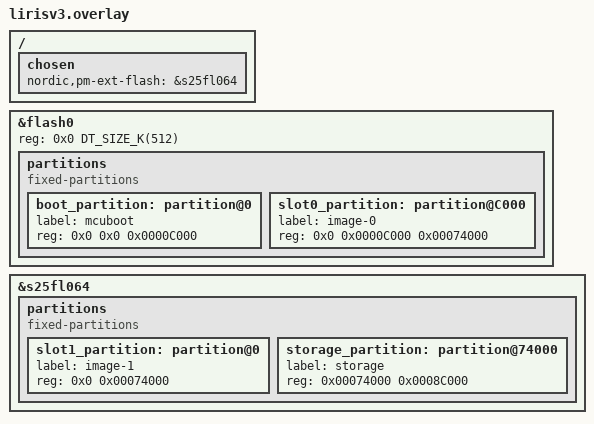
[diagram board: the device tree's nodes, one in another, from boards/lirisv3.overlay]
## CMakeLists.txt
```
#-------------------------------------------------------------------------------
# Zephyr Example Application
#
# Copyright (c) 2021 Nordic Semiconductor ASA
# SPDX-License-Identifier: Apache-2.0

cmake_minimum_required(VERSION 3.13.1)
find_package(Zephyr REQUIRED HINTS $ENV{ZEPHYR_BASE})

project(app LANGUAGES CXX C)

# Add C++ compiler flags
target_compile_options(app PRIVATE
  $<$<COMPILE_LANGUAGE:CXX>:-fno-threadsafe-statics>
)

target_sources(app PRIVATE src/main.cpp)
target_sources_ifdef(CONFIG_MCUMGR_TRANSPORT_BT app PRIVATE src/bluetooth.cpp)
```

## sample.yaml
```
# This file is provided so that the application can be compiled using Twister,
# the Zephyr testing tool. In this file, multiple combinations can be specified,
# so that you can easily test all of them locally or in CI.
sample:
  description: Example application
  name: example-application 
common:
  build_only: true
  integration_platforms:
    - lirisv4
tests:
  app.default: {}
  app.debug:
    extra_overlay_confs:
      - debug.conf
```

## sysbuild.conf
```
# Enable MCUboot bootloader support
SB_CONFIG_BOOTLOADER_MCUBOOT=y
```

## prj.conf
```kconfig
# Bootloader
CONFIG_BOOTLOADER_MCUBOOT=y

# C++ Support
CONFIG_CPP=y
CONFIG_STD_CPP11=y
# Disable everything that causes TLS / heavy runtime
CONFIG_CPP_EXCEPTIONS=n
CONFIG_CPP_RTTI=n
CONFIG_NEWLIB_LIBC=n
CONFIG_MINIMAL_LIBC=y

# Avoid TLS entirely
CONFIG_THREAD_LOCAL_STORAGE=n

# No heap / malloc
CONFIG_HEAP_MEM_POOL_SIZE=0

# MCUmgr and dependencies
CONFIG_NET_BUF=y
CONFIG_ZCBOR=y
CONFIG_CRC=y
CONFIG_MCUMGR=y
CONFIG_STREAM_FLASH=y
CONFIG_FLASH_MAP=y
CONFIG_IMG_MANAGER=y
CONFIG_MCUMGR_GRP_IMG=y
CONFIG_MCUMGR_GRP_OS=y
CONFIG_MCUMGR_GRP_OS_MCUMGR_PARAMS=y
CONFIG_MCUMGR_GRP_ZBASIC=y

# Bluetooth
CONFIG_BT=y
CONFIG_BT_PERIPHERAL=y
CONFIG_BT_L2CAP_TX_MTU=498
CONFIG_BT_BUF_EVT_RX_COUNT=4
CONFIG_BT_BUF_EVT_RX_SIZE=68
CONFIG_BT_BUF_ACL_TX_COUNT=3
CONFIG_BT_BUF_ACL_RX_SIZE=502
CONFIG_BT_BUF_ACL_TX_SIZE=502
CONFIG_BT_BUF_CMD_TX_COUNT=2
CONFIG_BT_CTLR_DATA_LENGTH_MAX=251

# MCUmgr Bluetooth transport
CONFIG_MCUMGR_TRANSPORT_BT=y
CONFIG_MCUMGR_TRANSPORT_BT_CONN_PARAM_CONTROL=y
CONFIG_MCUMGR_TRANSPORT_BT_REASSEMBLY=y
CONFIG_MCUMGR_TRANSPORT_NETBUF_SIZE=1024
CONFIG_MCUMGR_TRANSPORT_WORKQUEUE_STACK_SIZE=2048

# Flash and SPI
CONFIG_FLASH=y
CONFIG_SPI=y
CONFIG_SPI_NOR=y
CONFIG_SPI_NOR_FLASH_LAYOUT_PAGE_SIZE=4096
CONFIG_SPI_NRFX_RAM_BUFFER_SIZE=32

# File system
CONFIG_FILE_SYSTEM=y
CONFIG_FILE_SYSTEM_LITTLEFS=y

# DAC
CONFIG_DAC=y
CONFIG_LTC2640=y

# Stack sizes
CONFIG_SYSTEM_WORKQUEUE_STACK_SIZE=1536
CONFIG_MAIN_STACK_SIZE=1024
CONFIG_MPSL_WORK_STACK_SIZE=768

# Logging
CONFIG_LOG=y
CONFIG_LOG_MAX_LEVEL=2
CONFIG_LOG_MODE_MINIMAL=y
CONFIG_LOG_DEFAULT_LEVEL=2

# Boot banner
CONFIG_BOOT_BANNER=n
CONFIG_NCS_BOOT_BANNER=y
CONFIG_NCS_APPLICATION_BOOT_BANNER_STRING="LirisV4 Application"

# Disable debug/stats features
CONFIG_STATS=n
CONFIG_THREAD_MONITOR=n

# Memory optimization
CONFIG_SIZE_OPTIMIZATIONS=y
CONFIG_SPEED_OPTIMIZATIONS=n
CONFIG_DEBUG_OPTIMIZATIONS=n
CONFIG_COMPILER_OPT="-Os"
CONFIG_HEAP_MEM_POOL_SIZE=2048

# Disable debug features
CONFIG_DEBUG=n
CONFIG_ASSERT=n
CONFIG_ASSERT_VERBOSE=n

# Application-specific configurations
CONFIG_BLINK=y
```

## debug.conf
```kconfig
# Copyright (c) 2021 Nordic Semiconductor ASA
# SPDX-License-Identifier: Apache-2.0
#
# This is a Kconfig fragment which can be used to enable debug-related options
# in the application. See the README for more details.

# compiler
CONFIG_DEBUG_OPTIMIZATIONS=y

# logging
CONFIG_LOG=y
CONFIG_APP_LOG_LEVEL_DBG=y
```

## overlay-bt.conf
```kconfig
CONFIG_BT=y
CONFIG_BT_PERIPHERAL=y

# Allow for large Bluetooth data packets.
CONFIG_BT_L2CAP_TX_MTU=498
CONFIG_BT_BUF_ACL_RX_SIZE=502
CONFIG_BT_BUF_ACL_TX_SIZE=502
CONFIG_BT_CTLR_DATA_LENGTH_MAX=251

# Enable the Bluetooth mcumgr transport (unauthenticated).
CONFIG_MCUMGR_TRANSPORT_BT=y
CONFIG_MCUMGR_TRANSPORT_BT_CONN_PARAM_CONTROL=y

# Enable the mcumgr Packet Reassembly feature over Bluetooth and its configuration dependencies.
# MCUmgr buffer size is optimized to fit one SMP packet divided into five Bluetooth Write Commands,
# transmitted with the maximum possible MTU value: 498 bytes.
CONFIG_MCUMGR_TRANSPORT_BT_REASSEMBLY=y
CONFIG_MCUMGR_TRANSPORT_NETBUF_SIZE=2475
CONFIG_MCUMGR_GRP_OS_MCUMGR_PARAMS=y
CONFIG_MCUMGR_TRANSPORT_WORKQUEUE_STACK_SIZE=4608

# Enable the LittleFS file system.
CONFIG_FILE_SYSTEM=y
CONFIG_FILE_SYSTEM_LITTLEFS=y

# Enable the storage erase command.
CONFIG_MCUMGR_GRP_ZBASIC=y
CONFIG_MCUMGR_GRP_ZBASIC_STORAGE_ERASE=y
```

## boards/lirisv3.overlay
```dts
/ {
	chosen {
		nordic,pm-ext-flash = &s25fl064;
	};
};

&flash0 {
	reg = <0x0 DT_SIZE_K(512)>;

	partitions {
		compatible = "fixed-partitions";
		#address-cells = <2>;
		#size-cells = <1>;
		
		boot_partition: partition@0 {
			label = "mcuboot";
			reg = <0x0 0x0 0x0000C000>;
		};

		slot0_partition: partition@C000 {
			label = "image-0";
		    reg = <0x0 0x0000C000 0x00074000>;
        };
	};
};

&s25fl064 {
	status = "okay";

	partitions {
		compatible = "fixed-partitions";
		#address-cells = <1>;
		#size-cells = <1>;

		slot1_partition: partition@0 {
			label = "image-1";
			reg = <0x0 0x00074000>;
		};
		storage_partition: partition@74000 {
			label = "storage";
			reg = <0x00074000 0x0008C000>;
		};
	};
};
```

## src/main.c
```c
/*
 * Copyright (c) 2012-2014 Wind River Systems, Inc.
 * Copyright (c) 2020 Prevas A/S
 *
 * SPDX-License-Identifier: Apache-2.0
 */

#include <zephyr/kernel.h>
#include <zephyr/stats/stats.h>
#include <zephyr/usb/usb_device.h>

#ifdef CONFIG_MCUMGR_GRP_FS
#include <zephyr/device.h>
#include <zephyr/fs/fs.h>
#include <zephyr/fs/littlefs.h>
#endif
#ifdef CONFIG_MCUMGR_GRP_STAT
#include <zephyr/mgmt/mcumgr/grp/stat_mgmt/stat_mgmt.h>
#endif

#define LOG_LEVEL LOG_LEVEL_DBG
#include <zephyr/logging/log.h>
LOG_MODULE_REGISTER(smp_sample);

#include <drivers/blink.h>

#include "common.h"

#define STORAGE_PARTITION_LABEL	storage_partition
#define STORAGE_PARTITION_ID	FIXED_PARTITION_ID(STORAGE_PARTITION_LABEL)

/* Define an example stats group; approximates seconds since boot. */
STATS_SECT_START(smp_svr_stats)
STATS_SECT_ENTRY(ticks)
STATS_SECT_END;

/* Assign a name to the `ticks` stat. */
STATS_NAME_START(smp_svr_stats)
STATS_NAME(smp_svr_stats, ticks)
STATS_NAME_END(smp_svr_stats);

/* Define an instance of the stats group. */
STATS_SECT_DECL(smp_svr_stats) smp_svr_stats;

#ifdef CONFIG_MCUMGR_GRP_FS
FS_LITTLEFS_DECLARE_DEFAULT_CONFIG(cstorage);
static struct fs_mount_t littlefs_mnt = {
	.type = FS_LITTLEFS,
	.fs_data = &cstorage,
	.storage_dev = (void *)STORAGE_PARTITION_ID,
	.mnt_point = "/lfs1"
};
#endif

int main(void)
{
	const struct device *blink;

	blink = DEVICE_DT_GET(DT_NODELABEL(blink_led));
	if (!device_is_ready(blink)) {
		LOG_ERR("Blink LED not ready");
		return 0;
	}
	blink_set_period_ms(blink, 500);
	
	int rc = STATS_INIT_AND_REG(smp_svr_stats, STATS_SIZE_32,
				    "smp_svr_stats");

	if (rc < 0) {
		LOG_ERR("Error initializing stats system [%d]", rc);
	}

	/* Register the built-in mcumgr command handlers. */
#ifdef CONFIG_MCUMGR_GRP_FS
	rc = fs_mount(&littlefs_mnt);
	if (rc < 0) {
		LOG_ERR("Error mounting littlefs [%d]", rc);
	}
#endif

#ifdef CONFIG_MCUMGR_TRANSPORT_BT
	start_smp_bluetooth_adverts();
#endif

	/* using __TIME__ ensure that a new binary will be built on every
	 * compile which is convenient when testing firmware upgrade.
	 */
	LOG_INF("build time: " __DATE__ " " __TIME__);

	/* The system work queue handles all incoming mcumgr requests.  Let the
	 * main thread idle while the mcumgr server runs.
	 */
	while (1) {
		k_sleep(K_MSEC(1000));
		STATS_INC(smp_svr_stats, ticks);
	}
	return 0;
}
```

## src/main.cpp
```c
/*
 * Copyright (c) 2012-2014 Wind River Systems, Inc.
 * Copyright (c) 2020 Prevas A/S
 *
 * SPDX-License-Identifier: Apache-2.0
 */

#define LOG_LEVEL LOG_LEVEL_DBG
#include <zephyr/logging/log.h>

extern "C" {
#include <zephyr/kernel.h>
#include <zephyr/stats/stats.h>
#include <zephyr/usb/usb_device.h>

#ifdef CONFIG_MCUMGR_GRP_FS
#include <zephyr/device.h>
#include <zephyr/fs/fs.h>
#include <zephyr/fs/littlefs.h>
#endif
#ifdef CONFIG_MCUMGR_GRP_STAT
#include <zephyr/mgmt/mcumgr/grp/stat_mgmt/stat_mgmt.h>
#endif

#include <drivers/blink.h>
}

LOG_MODULE_REGISTER(smp_sample);

#include "common.h"

#define STORAGE_PARTITION_LABEL	storage_partition
#define STORAGE_PARTITION_ID	FIXED_PARTITION_ID(STORAGE_PARTITION_LABEL)

/* Define an example stats group; approximates seconds since boot. */
STATS_SECT_START(smp_svr_stats)
STATS_SECT_ENTRY(ticks)
STATS_SECT_END;

/* Assign a name to the `ticks` stat. */
STATS_NAME_START(smp_svr_stats)
STATS_NAME(smp_svr_stats, ticks)
STATS_NAME_END(smp_svr_stats);

/* Define an instance of the stats group. */
STATS_SECT_DECL(smp_svr_stats) smp_svr_stats;

#ifdef CONFIG_MCUMGR_GRP_FS
FS_LITTLEFS_DECLARE_DEFAULT_CONFIG(cstorage);
static struct fs_mount_t littlefs_mnt = {
	.type = FS_LITTLEFS,
	.fs_data = &cstorage,
	.storage_dev = (void *)STORAGE_PARTITION_ID,
	.mnt_point = "/lfs1"
};
#endif

/**
 * BlinkController - RAII class for managing the blink LED device
 * 
 * This class encapsulates LED device initialization and control,
 * following RAII principles for resource management.
 * 
 * Note: Initialization is performed separately from construction to allow
 * for error handling. Device initialization may fail if the hardware is not
 * ready, so we return a boolean from initialize() rather than throwing
 * exceptions (which are disabled in embedded systems).
 */
class BlinkController {
private:
	const struct device *blink_device;
	bool initialized;

public:
	/**
	 * Constructor - initializes member variables but does not initialize device.
	 * Device initialization is deferred to initialize() to allow proper error handling.
	 */
	BlinkController() : blink_device(nullptr), initialized(false) {
	}
	
	/**
	 * Initialize the blink LED device
	 * @return true if successful, false otherwise
	 */
	bool initialize() {
		blink_device = DEVICE_DT_GET(DT_NODELABEL(blink_led));
		if (!device_is_ready(blink_device)) {
			LOG_ERR("Blink LED not ready");
			initialized = false;
			return false;
		}
		initialized = true;
		return true;
	}
	
	/**
	 * Set the LED blink period
	 * @param period_ms Period in milliseconds
	 */
	void setPeriod(uint32_t period_ms) {
		if (initialized && blink_device) {
			blink_set_period_ms(blink_device, period_ms);
		}
	}
	
	/**
	 * Check if the controller is initialized
	 * @return true if initialized, false otherwise
	 */
	bool isInitialized() const {
		return initialized;
	}
};

/**
 * StatsManager - RAII class for managing statistics
 * 
 * This class encapsulates statistics initialization and management.
 */
class StatsManager {
private:
	bool initialized;

public:
	StatsManager() : initialized(false) {
	}
	
	/**
	 * Initialize the statistics system
	 * @return true if successful, false otherwise
	 */
	bool initialize() {
		int rc = STATS_INIT_AND_REG(smp_svr_stats, STATS_SIZE_32, "smp_svr_stats");
		if (rc < 0) {
			LOG_ERR("Error initializing stats system [%d]", rc);
			initialized = false;
			return false;
		}
		initialized = true;
		return true;
	}
	
	/**
	 * Increment the tick counter
	 */
	void incrementTicks() {
		if (initialized) {
			STATS_INC(smp_svr_stats, ticks);
		}
	}
	
	/**
	 * Check if the manager is initialized
	 * @return true if initialized, false otherwise
	 */
	bool isInitialized() const {
		return initialized;
	}
};

#ifdef CONFIG_MCUMGR_GRP_FS
/**
 * FileSystemManager - RAII class for managing filesystem mounting
 * 
 * This class encapsulates filesystem initialization and mounting,
 * following RAII principles.
 */
class FileSystemManager {
private:
	struct fs_mount_t *mount_point;
	bool mounted;

public:
	FileSystemManager(struct fs_mount_t *mnt) : mount_point(mnt), mounted(false) {
	}
	
	/**
	 * Mount the filesystem
	 * @return true if successful, false otherwise
	 */
	bool mount() {
		if (!mount_point) {
			return false;
		}
		
		int rc = fs_mount(mount_point);
		if (rc < 0) {
			LOG_ERR("Error mounting littlefs [%d]", rc);
			mounted = false;
			return false;
		}
		mounted = true;
		return true;
	}
	
	/**
	 * Check if filesystem is mounted
	 * @return true if mounted, false otherwise
	 */
	bool isMounted() const {
		return mounted;
	}
	
	/**
	 * Destructor - unmount filesystem if mounted
	 */
	~FileSystemManager() {
		if (mounted && mount_point) {
			fs_unmount(mount_point);
		}
	}
};
#endif

int main(void)
{
	// Initialize Blink LED Controller
	BlinkController blinkController;
	if (!blinkController.initialize()) {
		return 0;
	}
	blinkController.setPeriod(500);
	
	// Initialize Stats Manager
	// Note: Statistics failures are non-critical, so we continue even if initialization fails
	StatsManager statsManager;
	if (!statsManager.initialize()) {
		LOG_WRN("Statistics initialization failed, continuing without stats");
	}
	
	// Mount filesystem if configured
#ifdef CONFIG_MCUMGR_GRP_FS
	FileSystemManager fsManager(&littlefs_mnt);
	if (!fsManager.mount()) {
		LOG_WRN("Filesystem mounting failed, continuing without filesystem");
	}
#endif

	// Start Bluetooth advertising if configured
#ifdef CONFIG_MCUMGR_TRANSPORT_BT
	start_smp_bluetooth_adverts();
#endif

	/* using __TIME__ ensure that a new binary will be built on every
	 * compile which is convenient when testing firmware upgrade.
	 */
	LOG_INF("build time: " __DATE__ " " __TIME__);

	/* The system work queue handles all incoming mcumgr requests.  Let the
	 * main thread idle while the mcumgr server runs.
	 */
	while (1) {
		k_sleep(K_MSEC(1000));
		statsManager.incrementTicks();
	}
	return 0;
}
```

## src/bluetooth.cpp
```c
/*
 * Copyright (c) 2012-2014 Wind River Systems, Inc.
 * Copyright (c) 2020 Prevas A/S
 *
 * SPDX-License-Identifier: Apache-2.0
 */

#define LOG_LEVEL LOG_LEVEL_DBG
#include <zephyr/logging/log.h>

extern "C" {
#include <zephyr/bluetooth/bluetooth.h>
#include <zephyr/bluetooth/conn.h>
#include <zephyr/bluetooth/gatt.h>
#include <zephyr/bluetooth/hci.h>
#include <zephyr/mgmt/mcumgr/transport/smp_bt.h>
}

LOG_MODULE_REGISTER(smp_bt_sample);

// Bluetooth advertisement data
static const struct bt_data ad[] = {
	BT_DATA_BYTES(BT_DATA_FLAGS, (BT_LE_AD_GENERAL | BT_LE_AD_NO_BREDR)),
	BT_DATA_BYTES(BT_DATA_UUID128_ALL, SMP_BT_SVC_UUID_VAL),
};

static const struct bt_data sd[] = {
	BT_DATA(BT_DATA_NAME_COMPLETE, CONFIG_BT_DEVICE_NAME, sizeof(CONFIG_BT_DEVICE_NAME) - 1),
};

/**
 * BluetoothManager - Singleton class for managing Bluetooth functionality
 * 
 * This class encapsulates all Bluetooth operations including advertising,
 * connection management, and callbacks. The Singleton pattern ensures
 * only one instance manages the Bluetooth state.
 */
class BluetoothManager {
private:
	struct k_work advertise_work;
	
	// Private constructor for Singleton pattern
	BluetoothManager() {
		k_work_init(&advertise_work, advertiseCallback);
	}
	
	// Delete copy constructor and assignment operator
	BluetoothManager(const BluetoothManager&) = delete;
	BluetoothManager& operator=(const BluetoothManager&) = delete;
	
	/**
	 * Internal method to start advertising
	 */
	void advertise() {
		int rc = bt_le_adv_start(BT_LE_ADV_CONN_FAST_1, ad, ARRAY_SIZE(ad), sd, ARRAY_SIZE(sd));
		if (rc) {
			LOG_ERR("Advertising failed to start (rc %d)", rc);
			return;
		}
		LOG_INF("Advertising successfully started");
	}
	
	/**
	 * Internal method called when a connection is established
	 */
	void onConnected(struct bt_conn *conn, uint8_t err) {
		if (err) {
			LOG_ERR("Connection failed, err 0x%02x %s", err, bt_hci_err_to_str(err));
			k_work_submit(&advertise_work);
		} else {
			LOG_INF("Connected");
		}
	}
	
	/**
	 * Internal method called when a connection is disconnected
	 */
	void onDisconnected(struct bt_conn *conn, uint8_t reason) {
		LOG_INF("Disconnected, reason 0x%02x %s", reason, bt_hci_err_to_str(reason));
	}
	
	/**
	 * Internal method called when a connection is recycled
	 */
	void onConnRecycled() {
		k_work_submit(&advertise_work);
	}
	
	/**
	 * Internal method called when Bluetooth is ready
	 */
	void onBluetoothReady(int err) {
		if (err != 0) {
			LOG_ERR("Bluetooth failed to initialise: %d", err);
		} else {
			k_work_submit(&advertise_work);
		}
	}

public:
	/**
	 * Get the singleton instance
	 * Returns a reference to the single BluetoothManager instance.
	 * Uses a static local variable (Meyer's Singleton) to ensure
	 * thread-safe initialization and proper lifetime management.
	 */
	static BluetoothManager& getInstance() {
		static BluetoothManager instance;
		return instance;
	}
	
	/**
	 * Start Bluetooth advertising
	 */
	void start() {
		int rc = bt_enable(btReadyCallback);
		if (rc != 0) {
			LOG_ERR("Bluetooth enable failed: %d", rc);
		}
	}
	
	// Static callbacks for C API - these redirect to member functions
	static void advertiseCallback(struct k_work *work) {
		getInstance().advertise();
	}
	
	static void connectedCallback(struct bt_conn *conn, uint8_t err) {
		getInstance().onConnected(conn, err);
	}
	
	static void disconnectedCallback(struct bt_conn *conn, uint8_t reason) {
		getInstance().onDisconnected(conn, reason);
	}
	
	static void recycledCallback(void) {
		getInstance().onConnRecycled();
	}
	
	static void btReadyCallback(int err) {
		getInstance().onBluetoothReady(err);
	}
};

// Define connection callbacks using static methods
BT_CONN_CB_DEFINE(conn_callbacks) = {
	.connected = BluetoothManager::connectedCallback,
	.disconnected = BluetoothManager::disconnectedCallback,
	.recycled = BluetoothManager::recycledCallback,
};

// C-compatible interface function
extern "C" void start_smp_bluetooth_adverts(void)
{
	BluetoothManager::getInstance().start();
}
```

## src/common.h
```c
/*
 * Copyright (c) 2020 Prevas A/S
 *
 * SPDX-License-Identifier: Apache-2.0
 */

#ifndef COMMON_H
#define COMMON_H

#ifdef __cplusplus
extern "C" {
#endif

void start_smp_bluetooth_adverts(void);

#ifdef __cplusplus
}
#endif

#endif /* COMMON_H */
```
